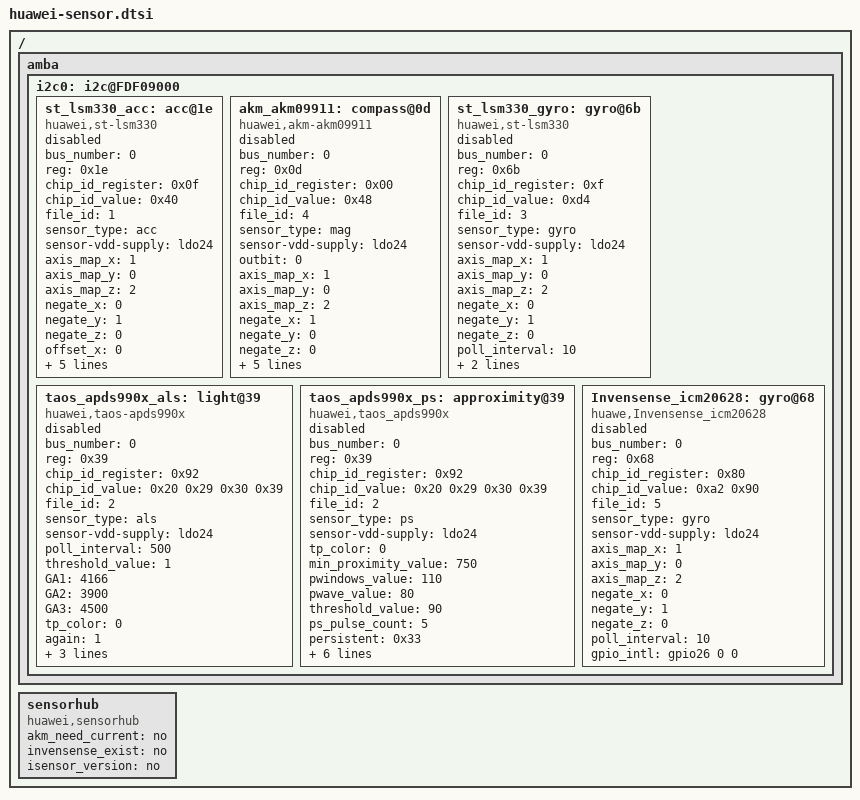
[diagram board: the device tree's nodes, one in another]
/{
    amba{
        i2c0: i2c@FDF09000{
            st_lsm330_acc:acc@1e{
                compatible="huawei,st-lsm330";
                bus_number=<0>;
                reg=<0x1e>;
                chip_id_register=<0x0f>;
                chip_id_value=<0x40>;
                file_id=<1>;
                sensor_type="acc";
                sensor-vdd-supply = <&ldo24>;
                axis_map_x=<1>;
                axis_map_y=<0>;
                axis_map_z=<2>;
                negate_x=<0>;
                negate_y=<1>;
                negate_z=<0>;
                offset_x=<0>;
                offset_y=<0>;
                offset_z=<0>;
                poll_interval=<10>;
                gpio_int1=<&gpio26 0 0>;
                gpio_int2=<&gpio8 3 0>;
                status = "disabled";
            };
            akm_akm09911:compass@0d{
                compatible="huawei,akm-akm09911";
                bus_number=<0>;
                reg=<0x0d>;
                chip_id_register=<0x00>;
                chip_id_value=<0x48>;
                file_id=<4>;
                sensor_type="mag";
                sensor-vdd-supply = <&ldo24>;
                outbit=<0>;
                axis_map_x=<1>;
                axis_map_y=<0>;
                axis_map_z=<2>;
                negate_x=<1>;
                negate_y=<0>;
                negate_z=<0>;
                poll_interval=<10>;
                gpio_int1=<&gpio0 0 0>;
                gpio_reset=<&gpio0 0 0>;
                softiron_parameter = <127 80 16 203 177 0 0 161 216 55 57 227 111 50 0 10 8 248 199 114 192 252 23 59 11 196 81>;
                status = "disabled";
            };
            st_lsm330_gyro:gyro@6b{
                compatible ="huawei,st-lsm330";
                bus_number=<0>;
                reg=<0x6b>;
                chip_id_register=<0xf>;
                chip_id_value=<0xd4>;
                file_id=<3>;
                sensor_type="gyro";
                sensor-vdd-supply = <&ldo24>;
                axis_map_x=<1>;
                axis_map_y=<0>;
                axis_map_z=<2>;
                negate_x=<0>;
                negate_y=<1>;
                negate_z=<0>;
                poll_interval=<10>;
                gpio_int1=<&gpio26 2 0>;
                gpio_int2=<&gpio8 3 0>;
                status = "disabled";
            };
            taos_apds990x_als:light@39{
                compatible="huawei,taos-apds990x";
                bus_number=<0>;
                reg=<0x39>;
                chip_id_register=<0x92>;
                chip_id_value=<0x20 0x29 0x30 0x39>;
                file_id=<2>;
                sensor_type="als";
                sensor-vdd-supply = <&ldo24>;
                poll_interval=<500>;   //环境光轮询最小时间间隔
                threshold_value=<1>;
                GA1=<4166>; //玻璃透光率 ，3种光源
                GA2=<3900>; //玻璃透光率
                GA3=<4500>; //玻璃透光率
                tp_color =<0>;
                again=<1>;
                gpio_int1=<&gpio25 6 0>;
                atime=<0xdb>;
                init_time = <150>;   //环境光初始化时间
                status = "disabled";
            };
            taos_apds990x_ps:approximity@39{
                compatible="huawei,taos_apds990x";
                bus_number=<0>;
                reg=<0x39>;
                chip_id_register=<0x92>;
                chip_id_value=<0x20 0x29 0x30 0x39>;
                file_id=<2>;
                sensor_type="ps";
                sensor-vdd-supply = <&ldo24>;
                tp_color =<0>;
                min_proximity_value=<750>;
                pwindows_value=<110>;
                pwave_value=<80>;
                threshold_value=<90>;
                ps_pulse_count=<5>;
                persistent=<0x33>;
                rdata_under_sun=<5500>;
                gpio_int1=<&gpio25 6 0>;
                ptime=<0xFF>;
                p_on = <0>;   //睡眠期间是否需要关闭晶振
                poll_interval = <300>;
                init_time = <50>;
                status = "disabled";
            };
	    Invensense_icm20628:gyro@68{
                compatible="huawe,Invensense_icm20628";
                bus_number=<0>;
                reg=<0x68>;
                chip_id_register=<0x80>;
                chip_id_value=<0xa2 0x90>;
                file_id=<5>;
                sensor_type="gyro";
                sensor-vdd-supply = <&ldo24>;
                axis_map_x=<1>;
                axis_map_y=<0>;
                axis_map_z=<2>;
                negate_x=<0>;
                negate_y=<1>;
                negate_z=<0>;
                poll_interval=<10>;
                gpio_intl=<&gpio26 0 0>;
                status = "disabled";
            };
        };
    };
    sensorhub: sensorhub {
        compatible = "huawei,sensorhub";
        akm_need_current = "no";
        invensense_exist = "no";
        isensor_version= "no";
    };
};
